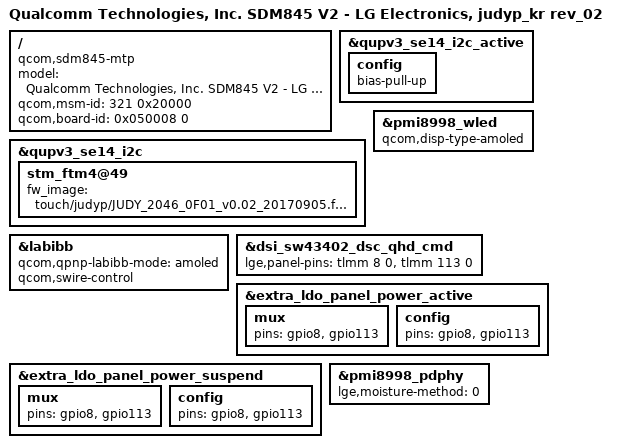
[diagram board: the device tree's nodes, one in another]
/* Copyright (c) 2017, The Linux Foundation. All rights reserved.
 *
 * This program is free software; you can redistribute it and/or modify
 * it under the terms of the GNU General Public License version 2 and
 * only version 2 as published by the Free Software Foundation.
 *
 * This program is distributed in the hope that it will be useful,
 * but WITHOUT ANY WARRANTY; without even the implied warranty of
 * MERCHANTABILITY or FITNESS FOR A PARTICULAR PURPOSE.  See the
 * GNU General Public License for more details.
 */


/dts-v1/;
/plugin/;

#include "sdm845-judyp_kr.dtsi"
#include "../sdm845-judy_common/sdm845-judy_common-sound_es9218p.dtsi"
#include "sdm845-judyp_kr-tdmb_rev-0.2.dtsi"

/ {
	model = "Qualcomm Technologies, Inc. SDM845 V2 - LG Electronics, judyp_kr rev_02";
	compatible = "qcom,sdm845-mtp", "qcom,sdm845", "qcom,mtp";
	qcom,msm-id = <321 0x20000>;
	qcom,board-id = <0x050008 0>;
};

&qupv3_se14_i2c_active {
	config {
		bias-pull-up;
	};
};

&qupv3_se14_i2c {
        stm_ftm4@49 {
                fw_image = "touch/judyp/JUDY_2046_0F01_v0.02_20170905.ftb";
        };
};

&labibb {
	status = "ok";
	qcom,qpnp-labibb-mode = "amoled";
	qcom,swire-control;
};

&pmi8998_wled {
	status = "ok";
	qcom,disp-type-amoled;
};

&dsi_sw43402_dsc_qhd_cmd {
	lge,panel-pins =
		<&tlmm 8 0>,  // vddio
		<&tlmm 113 0>; // vpnl
};

&extra_ldo_panel_power_active {
	mux {
		pins = "gpio8", "gpio113";
	};

	config {
		pins = "gpio8", "gpio113";
	};

};

&extra_ldo_panel_power_suspend {
	mux {
		pins = "gpio8", "gpio113";
	};

	config {
		pins = "gpio8", "gpio113";
	};
};

&pmi8998_pdphy {
	lge,moisture-method = <0>;
};
